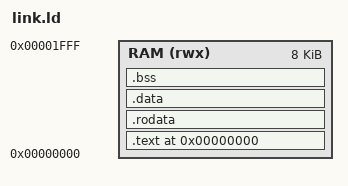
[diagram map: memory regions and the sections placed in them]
/* link.ld - Minimal bare-metal linker script for rv32i_cpu
   Places everything starting at address 0, matching RESET_PC. */
ENTRY(_start)

MEMORY
{
    RAM (rwx) : ORIGIN = 0x00000000, LENGTH = 8K
}

SECTIONS
{
    . = 0x00000000;

    .text : {
        *(.text.start)
        *(.text*)
    } > RAM

    .rodata : {
        *(.rodata*)
    } > RAM

    .data : {
        *(.data*)
    } > RAM

    .bss : {
        *(.bss*)
        *(COMMON)
    } > RAM
}
